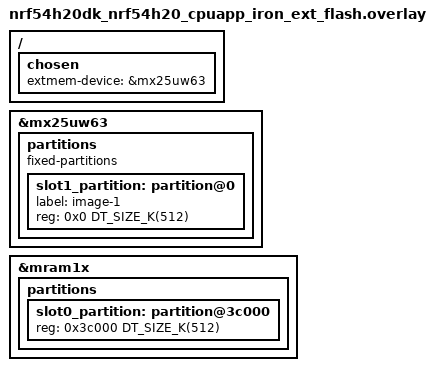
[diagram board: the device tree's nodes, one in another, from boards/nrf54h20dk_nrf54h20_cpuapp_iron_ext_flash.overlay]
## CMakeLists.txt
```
cmake_minimum_required(VERSION 3.20.0)
# Top-level CMakeLists.txt for the skeleton application.
#
# Copyright (c) 2017 Open Source Foundries Limited
#
# SPDX-License-Identifier: Apache-2.0
#
# This provides a basic application structure suitable for communication using
# mcumgr.  It can be used as a starting point for new applications.

# Standard Zephyr application boilerplate.

if (EXISTS "${CMAKE_CURRENT_SOURCE_DIR}/configuration/${BOARD}")
  message(WARNING
          "Board specific configuration will be used for ${BOARD} "
          "When providing -DOVERLAY_CONFIG= remember that all overlay "
          "configuration paths are relative to "
          "${CMAKE_CURRENT_SOURCE_DIR}/configuration/${BOARD}")
  set(APPLICATION_CONFIG_DIR "configuration/\${BOARD}")
else()
  message(NOTICE
          "Board ${BOARD} does not have board specific configuration.\n")
endif()

find_package(Zephyr REQUIRED HINTS $ENV{ZEPHYR_BASE})

project(smp_svr)

target_sources(app PRIVATE src/main.c)
target_sources_ifdef(CONFIG_MCUMGR_TRANSPORT_BT app PRIVATE src/bluetooth.c)
```

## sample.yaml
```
sample:
  description: Simple Management Protocol sample
  name: smp svr
common:
  sysbuild: true
  build_only: true
tests:
  sample.mcumgr.smp_svr.bt:
    harness: bluetooth
    tags: bluetooth
    extra_args: EXTRA_CONF_FILE="bt.conf"
    platform_allow:
      - nrf52dk/nrf52832
      - nrf52840dk/nrf52840
      - pinnacle_100_dvk
      - mg100
    integration_platforms:
      - nrf52dk/nrf52832
      - nrf52840dk/nrf52840
  sample.mcumgr.smp_svr.bt_static_svc:
    harness: bluetooth
    tags: bluetooth
    extra_args: EXTRA_CONF_FILE="bt.conf"
    extra_configs:
      - CONFIG_MCUMGR_TRANSPORT_BT_DYNAMIC_SVC_REGISTRATION=n
    platform_allow:
      - nrf52840dk/nrf52840
      - pinnacle_100_dvk
      - mg100
    integration_platforms:
      - nrf52840dk/nrf52840
  sample.mcumgr.smp_svr.udp:
    extra_args: EXTRA_CONF_FILE="udp.conf"
    platform_allow:
      - frdm_mcxn947/mcxn947/cpu0
      - mcx_n9xx_evk/mcxn947/cpu0
      - frdm_k64f
    integration_platforms:
      - frdm_k64f
  # Uses prj_no_bootloader.conf instead of prj.conf: this is the only scenario
  # built without MCUboot, so the image-management settings prj.conf carries for
  # every other scenario cannot take effect here.
  sample.mcumgr.smp_svr.udp-dtls:
    extra_args:
      - FILE_SUFFIX="no_bootloader"
      - EXTRA_CONF_FILE="udp-dtls.conf"
    platform_allow:
      - native_sim
    integration_platforms:
      - native_sim
    build_only: true
  sample.mcumgr.smp_svr.udp.802154.subg:
    extra_args: EXTRA_CONF_FILE="udp.conf;802154-subg.conf"
    platform_allow: beagleconnect_freedom
  sample.mcumgr.smp_svr.cdc:
    extra_args:
      - EXTRA_CONF_FILE="cdc.conf"
      - DTC_OVERLAY_FILE="usb.overlay"
    platform_allow:
      - frdm_mcxn947/mcxn947/cpu0
      - mcx_n9xx_evk/mcxn947/cpu0
      - nrf52833dk/nrf52820
      - nrf52833dk/nrf52833
      - nrf52840dk/nrf52840
      - nrf5340dk/nrf5340/cpuapp
      - pinnacle_100_dvk
    integration_platforms:
      - nrf52833dk/nrf52820
      - nrf52833dk/nrf52833
      - nrf52840dk/nrf52840
      - nrf5340dk/nrf5340/cpuapp
  sample.mcumgr.smp_svr.serial:
    extra_args: EXTRA_CONF_FILE="serial.conf"
    platform_allow:
      - frdm_k22f
      - frdm_k64f
      - frdm_k82f
      - frdm_ke17z
      - frdm_ke17z512
      - rddrone_fmuk66
      - twr_ke18f
      - twr_kv58f220m
      - frdm_mcxn947/mcxn947/cpu0
      - mcx_n9xx_evk/mcxn947/cpu0
      - lpcxpresso55s06
      - lpcxpresso55s16
      - lpcxpresso55s28
      - lpcxpresso55s36
      - lpcxpresso55s69/lpc55s69/cpu0
      - mimxrt1010_evk
      - mimxrt1015_evk
      - mimxrt1020_evk
      - mimxrt1024_evk
      - mimxrt1040_evk
      - mimxrt1050_evk/mimxrt1052/hyperflash
      - mimxrt1060_evk/mimxrt1062/qspi
      - mimxrt1062_fmurt6
      - mimxrt1064_evk
      - mimxrt1160_evk/mimxrt1166/cm7
      - mimxrt1170_evk/mimxrt1176/cm7
      - vmu_rt1170/mimxrt1176/cm7
      - mimxrt595_evk/mimxrt595s/cm33
      - mimxrt685_evk/mimxrt685s/cm33
      - rd_rw612_bga
      - nrf52840dk/nrf52840
      - nrf54h20dk/nrf54h20/cpuapp
      - pinnacle_100_dvk
      - mg100
    integration_platforms:
      - nrf52840dk/nrf52840
  # In mcuboot_flags test serial.conf is used for convenience as it is the simplest
  # transport. Transport does not affect flags so it does not really matter which is selected,
  # flags should affect any transport the same way.
  sample.mcumgr.smp_svr.mcuboot_flags.direct_xip_withrevert:
    extra_args:
      - EXTRA_CONF_FILE="serial.conf"
      - SB_CONFIG_MCUBOOT_MODE_DIRECT_XIP_WITH_REVERT=y
    platform_allow:
      - nrf52840dk/nrf52840
      - pinnacle_100_dvk
      - mg100
    integration_platforms:
      - nrf52840dk/nrf52840
  sample.mcumgr.smp_svr.serial-console:
    extra_args: EXTRA_CONF_FILE="serial-console.conf"
    platform_allow:
      - nrf52840dk/nrf52840
      - pinnacle_100_dvk
      - mg100
    integration_platforms:
      - nrf52840dk/nrf52840
  sample.mcumgr.smp_svr.shell:
    extra_args: EXTRA_CONF_FILE="shell.conf"
    platform_allow:
      - frdm_k22f
      - frdm_k64f
      - frdm_k82f
      - frdm_ke17z
      - frdm_ke17z512
      - rddrone_fmuk66
      - twr_ke18f
      - twr_kv58f220m
      - frdm_mcxn947/mcxn947/cpu0
      - mcx_n9xx_evk/mcxn947/cpu0
      - lpcxpresso55s06
      - lpcxpresso55s16
      - lpcxpresso55s28
      - lpcxpresso55s36
      - lpcxpresso55s69/lpc55s69/cpu0
      - mimxrt1010_evk
      - mimxrt1015_evk
      - mimxrt1020_evk
      - mimxrt1024_evk
      - mimxrt1040_evk
      - mimxrt1050_evk/mimxrt1052/hyperflash
      - mimxrt1060_evk/mimxrt1062/qspi
      - mimxrt1062_fmurt6
      - mimxrt1064_evk
      - mimxrt1160_evk/mimxrt1166/cm7
      - mimxrt1170_evk/mimxrt1176/cm7
      - vmu_rt1170/mimxrt1176/cm7
      - mimxrt595_evk/mimxrt595s/cm33
      - mimxrt685_evk/mimxrt685s/cm33
      - rd_rw612_bga
      - nrf52840dk/nrf52840
      - pinnacle_100_dvk
      - mg100
    integration_platforms:
      - nrf52840dk/nrf52840
      - mimxrt1060_evk/mimxrt1062/qspi
      - mimxrt1064_evk
  sample.mcumgr.smp_svr.shell_mgmt:
    extra_args: EXTRA_CONF_FILE="shell-mgmt.conf"
    platform_allow:
      - nrf52840dk/nrf52840
      - pinnacle_100_dvk
      - mg100
    integration_platforms:
      - nrf52840dk/nrf52840
  sample.mcumgr.smp_svr.fs:
    extra_args: EXTRA_CONF_FILE="fs.conf"
    platform_allow:
      - nrf52840dk/nrf52840
      - pinnacle_100_dvk
      - mg100
    integration_platforms:
      - nrf52840dk/nrf52840
  sample.mcumgr.smp_svr.ram_load:
    extra_args: FILE_SUFFIX="ram_load"
    platform_allow:
      - nrf52840dk/nrf52840
    integration_platforms:
      - nrf52840dk/nrf52840
  sample.mcumgr.smp_svr.ram_load.serial:
    extra_args:
      - FILE_SUFFIX="ram_load"
      - EXTRA_CONF_FILE="serial.conf"
    platform_allow:
      - nrf52840dk/nrf52840
      - mimxrt1050_evk/mimxrt1052/hyperflash
  sample.mcumgr.smp_svr.ram_load_revert.serial:
    extra_args:
      - FILE_SUFFIX="ram_load"
      - EXTRA_CONF_FILE="serial.conf"
      - SB_CONFIG_MCUBOOT_MODE_RAM_LOAD_WITH_REVERT=y
      - smp_svr_CONFIG_MCUBOOT_GENERATE_CONFIRMED_IMAGE=y
    platform_allow:
      - mimxrt1050_evk/mimxrt1052/hyperflash
    integration_platforms:
      - mimxrt1050_evk/mimxrt1052/hyperflash
  sample.mcumgr.smp_svr.raw-serial.fs:
    extra_args: EXTRA_CONF_FILE="raw-serial.conf;fs.conf"
    platform_allow:
      - nrf52840dk/nrf52840
    integration_platforms:
      - nrf52840dk/nrf52840
```

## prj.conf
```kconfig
# Enable MCUmgr and dependencies.
CONFIG_NET_BUF=y
CONFIG_ZCBOR=y
CONFIG_CRC=y
CONFIG_MCUMGR=y
CONFIG_STREAM_FLASH=y
CONFIG_FLASH_MAP=y

# Some command handlers require a large stack.
CONFIG_SYSTEM_WORKQUEUE_STACK_SIZE=2304
CONFIG_MAIN_STACK_SIZE=2176

# Ensure an MCUboot-compatible binary is generated.
CONFIG_BOOTLOADER_MCUBOOT=y

# Enable flash operations.
CONFIG_FLASH=y

# Required by the `taskstat` command.
CONFIG_THREAD_MONITOR=y

# Support for taskstat command
CONFIG_MCUMGR_GRP_OS_TASKSTAT=y

# Enable statistics and statistic names.
CONFIG_STATS=y
CONFIG_STATS_NAMES=y

# Enable most core commands.
CONFIG_FLASH=y
CONFIG_IMG_MANAGER=y
CONFIG_MCUMGR_GRP_IMG=n
CONFIG_MCUMGR_GRP_OS=y
CONFIG_MCUMGR_GRP_STAT=y

# Enable logging
CONFIG_LOG=y
CONFIG_MCUBOOT_UTIL_LOG_LEVEL_WRN=n

# Disable debug logging
CONFIG_LOG_MAX_LEVEL=3
```

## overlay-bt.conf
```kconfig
CONFIG_BT=y
CONFIG_BT_PERIPHERAL=y

# Allow for large Bluetooth data packets.
CONFIG_BT_L2CAP_TX_MTU=498
CONFIG_BT_BUF_ACL_RX_SIZE=502
CONFIG_BT_BUF_ACL_TX_SIZE=502
CONFIG_BT_CTLR_DATA_LENGTH_MAX=251

# Enable the Bluetooth mcumgr transport (unauthenticated).
CONFIG_MCUMGR_TRANSPORT_BT=y
CONFIG_MCUMGR_TRANSPORT_BT_AUTHEN=n
CONFIG_MCUMGR_TRANSPORT_BT_CONN_PARAM_CONTROL=y

# Enable the Shell mcumgr transport.
CONFIG_BASE64=y
CONFIG_CRC=y
CONFIG_SHELL=y
CONFIG_SHELL_BACKEND_SERIAL=y
CONFIG_MCUMGR_TRANSPORT_SHELL=y

# Enable the mcumgr Packet Reassembly feature over Bluetooth and its configuration dependencies.
# MCUmgr buffer size is optimized to fit one SMP packet divided into five Bluetooth Write Commands,
# transmitted with the maximum possible MTU value: 498 bytes.
CONFIG_MCUMGR_TRANSPORT_BT_REASSEMBLY=y
CONFIG_MCUMGR_TRANSPORT_NETBUF_SIZE=2475
CONFIG_MCUMGR_GRP_OS_MCUMGR_PARAMS=y
CONFIG_MCUMGR_TRANSPORT_WORKQUEUE_STACK_SIZE=4608

CONFIG_MCUMGR_TRANSPORT_BT_CONN_PARAM_CONTROL_MIN_INT=30
CONFIG_MCUMGR_TRANSPORT_BT_CONN_PARAM_CONTROL_MAX_INT=50
CONFIG_MCUMGR_TRANSPORT_BT_CONN_PARAM_CONTROL_TIMEOUT=400
CONFIG_BT_PERIPHERAL_PREF_MIN_INT=30
CONFIG_BT_PERIPHERAL_PREF_MAX_INT=50
CONFIG_BT_PERIPHERAL_PREF_TIMEOUT=400

# Enable the LittleFS file system.
CONFIG_FILE_SYSTEM=y
CONFIG_FILE_SYSTEM_LITTLEFS=y

# Enable file system commands
CONFIG_MCUMGR_GRP_FS=y

# Enable the storage erase command.
CONFIG_MCUMGR_GRP_ZBASIC=y
CONFIG_MCUMGR_GRP_ZBASIC_STORAGE_ERASE=y

# Disable Bluetooth ping support
CONFIG_BT_CTLR_LE_PING=n

# Disable shell commands that are not needed
CONFIG_CLOCK_CONTROL_NRF_SHELL=n
CONFIG_DEVICE_SHELL=n
CONFIG_DEVMEM_SHELL=n
CONFIG_FLASH_SHELL=n
```

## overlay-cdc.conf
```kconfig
# Enable USB subsystem
CONFIG_USB_DEVICE_STACK=y
CONFIG_SERIAL=y
CONFIG_UART_LINE_CTRL=y
CONFIG_USB_DEVICE_INITIALIZE_AT_BOOT=n
CONFIG_CONSOLE=y
# USB backend is serial device
CONFIG_MCUMGR_SMP_UART=y
```

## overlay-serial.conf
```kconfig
# Enable the serial mcumgr transport.
CONFIG_MCUMGR_SMP_UART=y
CONFIG_CONSOLE=y
```

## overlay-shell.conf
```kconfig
# Enable the shell mcumgr transport.
CONFIG_SHELL=y
CONFIG_SHELL_BACKEND_SERIAL=y
CONFIG_MCUMGR_SMP_SHELL=y

# mcumgr-cli application doesn't accepts log in the channel it uses
CONFIG_SHELL_LOG_BACKEND=n
```

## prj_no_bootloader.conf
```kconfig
# Variant of prj.conf for the scenarios that build without a bootloader.
#
# prj.conf turns on image management, which only makes sense when MCUboot owns a
# second slot. Without a bootloader IMG_MANAGER stays off, and with it both
# MCUMGR_GRP_IMG and the whole MCUBOOT_UTIL log level choice become unreachable,
# so those assignments could never take effect here. The rest is identical to
# prj.conf.

# Enable MCUmgr and dependencies.
CONFIG_NET_BUF=y
CONFIG_ZCBOR=y
CONFIG_CRC=y
CONFIG_MCUMGR=y
CONFIG_STREAM_FLASH=y
CONFIG_FLASH_MAP=y

# Some command handlers require a large stack.
CONFIG_SYSTEM_WORKQUEUE_STACK_SIZE=2304
CONFIG_MAIN_STACK_SIZE=2176

# Enable flash operations.
CONFIG_FLASH=y

# Required by the `taskstat` command.
CONFIG_THREAD_MONITOR=y

# Support for taskstat command
CONFIG_MCUMGR_GRP_OS_TASKSTAT=y

# Enable statistics and statistic names.
CONFIG_STATS=y
CONFIG_STATS_NAMES=y

# Enable most core commands.
CONFIG_FLASH=y
# Ineffective without a bootloader: MCUMGR_GRP_IMG depends on IMG_MANAGER.
# CONFIG_IMG_MANAGER=y
# CONFIG_MCUMGR_GRP_IMG=y
CONFIG_MCUMGR_GRP_OS=y
CONFIG_MCUMGR_GRP_STAT=y

# Enable logging
CONFIG_LOG=y
# Ineffective without a bootloader: the MCUBOOT_UTIL log level choice only
# exists once IMG_MANAGER pulls in MCUBOOT_BOOTUTIL_LIB.
# CONFIG_MCUBOOT_UTIL_LOG_LEVEL_WRN=y

# Disable debug logging
CONFIG_LOG_MAX_LEVEL=3
```

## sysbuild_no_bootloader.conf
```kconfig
# Companion of prj_no_bootloader.conf: build the application on its own.
SB_CONFIG_BOOTLOADER_NONE=y
```

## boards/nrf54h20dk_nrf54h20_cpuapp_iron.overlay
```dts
/ {
	sram@22007FC0 {
		compatible = "zephyr,memory-region", "mmio-sram";
		reg = <0x22007FC0 0x40>;
		zephyr,memory-region = "RetainedMem";
		status = "okay";

		retainedmem {
			compatible = "zephyr,retained-ram";
			status = "okay";
			#address-cells = <1>;
			#size-cells = <1>;

			boot_info0: boot_info@0 {
				compatible = "zephyr,retention";
				status = "okay";
				reg = <0x0 0x40>;
			};
		};
	};

	chosen {
		zephyr,bootloader-info = &boot_info0;
	};
};

&cpuapp_ram0 {
	reg = <0x22000000 0x7FC0>;
};
```

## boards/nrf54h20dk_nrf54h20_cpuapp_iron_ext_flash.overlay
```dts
/*
 * Copyright (c) 2025 Nordic Semiconductor ASA
 *
 * SPDX-License-Identifier: LicenseRef-Nordic-5-Clause
 */

/delete-node/ &slot1_partition;

/ {
	chosen {
		extmem-device = &mx25uw63;
	};
};

&mx25uw63 {
	status = "okay";
	partitions {
		compatible = "fixed-partitions";
		#address-cells = <1>;
		#size-cells = <1>;

		slot1_partition: partition@0 {
			label = "image-1";
			reg = <0x0 DT_SIZE_K(512)>;
		};
	};
};

&mram1x {
	partitions {
		slot0_partition: partition@3c000 {
			reg = <0x3c000 DT_SIZE_K(512)>;
		};
	};
};
```

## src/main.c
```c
/*
 * Copyright (c) 2012-2014 Wind River Systems, Inc.
 * Copyright (c) 2020 Prevas A/S
 *
 * SPDX-License-Identifier: Apache-2.0
 */

#include <zephyr/kernel.h>
#include <zephyr/stats/stats.h>
#include <zephyr/usb/usb_device.h>

#ifdef CONFIG_MCUMGR_GRP_FS
#include <zephyr/device.h>
#include <zephyr/fs/fs.h>
#include <zephyr/fs/littlefs.h>
#endif
#ifdef CONFIG_MCUMGR_GRP_STAT
#include <zephyr/mgmt/mcumgr/grp/stat_mgmt/stat_mgmt.h>
#endif

#define LOG_LEVEL LOG_LEVEL_DBG
#include <zephyr/logging/log.h>
LOG_MODULE_REGISTER(smp_sample);

#include "common.h"

#include <zephyr/retention/blinfo.h>
#include <bootutil/image.h>

#define STORAGE_PARTITION_LABEL	storage_partition
#define STORAGE_PARTITION_ID	FIXED_PARTITION_ID(STORAGE_PARTITION_LABEL)

/* Define an example stats group; approximates seconds since boot. */
STATS_SECT_START(smp_svr_stats)
STATS_SECT_ENTRY(ticks)
STATS_SECT_END;

/* Assign a name to the `ticks` stat. */
STATS_NAME_START(smp_svr_stats)
STATS_NAME(smp_svr_stats, ticks)
STATS_NAME_END(smp_svr_stats);

/* Define an instance of the stats group. */
STATS_SECT_DECL(smp_svr_stats) smp_svr_stats;

#ifdef CONFIG_MCUMGR_GRP_FS
FS_LITTLEFS_DECLARE_DEFAULT_CONFIG(cstorage);
static struct fs_mount_t littlefs_mnt = {
	.type = FS_LITTLEFS,
	.fs_data = &cstorage,
	.storage_dev = (void *)STORAGE_PARTITION_ID,
	.mnt_point = "/lfs1"
};
#endif

static void blinfo_bootloader_version(void)
{
	struct image_version version = {0x00};

	int ret = blinfo_lookup(BLINFO_BOOTLOADER_VERSION,
				(char *)&version,
				sizeof(struct image_version));

	if (ret < 0) {
		printf("blinfo_lookup error: %d\n", ret);
	} else {
		printf("bl iv_major: %d\n", version.iv_major);
		printf("bl iv_minor: %d\n", version.iv_minor);
		printf("bl iv_revision: %d\n", version.iv_revision);
		printf("bl iv_build_num: %d\n", version.iv_build_num);
	}
}

int main(void)
{
	int rc = STATS_INIT_AND_REG(smp_svr_stats, STATS_SIZE_32,
				    "smp_svr_stats");

	if (rc < 0) {
		LOG_ERR("Error initializing stats system [%d]", rc);
	}

	/* Register the built-in mcumgr command handlers. */
#ifdef CONFIG_MCUMGR_GRP_FS
	rc = fs_mount(&littlefs_mnt);
	if (rc < 0) {
		LOG_ERR("Error mounting littlefs [%d]", rc);
	}
#endif

#ifdef CONFIG_MCUMGR_TRANSPORT_BT
	start_smp_bluetooth_adverts();
#endif

	if (IS_ENABLED(CONFIG_USB_DEVICE_STACK)) {
		rc = usb_enable(NULL);

		/* Ignore EALREADY error as USB CDC is likely already initialised */
		if (rc != 0 && rc != -EALREADY) {
			LOG_ERR("Failed to enable USB");
			return 0;
		}
	}
	/* using __TIME__ ensure that a new binary will be built on every
	 * compile which is convenient when testing firmware upgrade.
	 */
	LOG_INF("build time: " __DATE__ " " __TIME__);

	blinfo_bootloader_version();

	/* The system work queue handles all incoming mcumgr requests.  Let the
	 * main thread idle while the mcumgr server runs.
	 */
	while (1) {
		k_sleep(K_MSEC(1000));
		STATS_INC(smp_svr_stats, ticks);
	}
	return 0;
}
```

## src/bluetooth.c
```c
/*
 * Copyright (c) 2012-2014 Wind River Systems, Inc.
 * Copyright (c) 2020 Prevas A/S
 *
 * SPDX-License-Identifier: Apache-2.0
 */

#include <zephyr/bluetooth/bluetooth.h>
#include <zephyr/bluetooth/conn.h>
#include <zephyr/bluetooth/gatt.h>
#include <zephyr/bluetooth/hci.h>
#include <zephyr/mgmt/mcumgr/transport/smp_bt.h>

#define LOG_LEVEL LOG_LEVEL_DBG
#include <zephyr/logging/log.h>
LOG_MODULE_REGISTER(smp_bt_sample);

static struct k_work advertise_work;

static const struct bt_data ad[] = {
	BT_DATA_BYTES(BT_DATA_FLAGS, (BT_LE_AD_GENERAL | BT_LE_AD_NO_BREDR)),
	BT_DATA_BYTES(BT_DATA_UUID128_ALL, SMP_BT_SVC_UUID_VAL),
};

static const struct bt_data sd[] = {
	BT_DATA(BT_DATA_NAME_COMPLETE, CONFIG_BT_DEVICE_NAME, sizeof(CONFIG_BT_DEVICE_NAME) - 1),
};

static void advertise(struct k_work *work)
{
	int rc;

	rc = bt_le_adv_start(BT_LE_ADV_CONN_FAST_1, ad, ARRAY_SIZE(ad), sd, ARRAY_SIZE(sd));
	if (rc) {
		LOG_ERR("Advertising failed to start (rc %d)", rc);
		return;
	}

	LOG_INF("Advertising successfully started");
}

static void connected(struct bt_conn *conn, uint8_t err)
{
	if (err) {
		LOG_ERR("Connection failed, err 0x%02x %s", err, bt_hci_err_to_str(err));
		k_work_submit(&advertise_work);
	} else {
		struct bt_conn_info info;
		char peer[BT_ADDR_LE_STR_LEN] = "unknown";
		char local[BT_ADDR_LE_STR_LEN] = "unknown";
		int rc;

		rc = bt_conn_get_info(conn, &info);
		if (rc) {
			LOG_WRN("Failed to get connection info (rc %d)", rc);
		} else {
			bt_addr_le_to_str(info.le.remote, peer, sizeof(peer));
			bt_addr_le_to_str(info.le.local, local, sizeof(local));
		}

		LOG_INF("Connected, peer %s, local %s", peer, local);
	}
}

static void disconnected(struct bt_conn *conn, uint8_t reason)
{
	struct bt_conn_info info;
	char peer[BT_ADDR_LE_STR_LEN] = "unknown";
	int rc;

	rc = bt_conn_get_info(conn, &info);
	if (rc) {
		LOG_WRN("Failed to get connection info (rc %d)", rc);
	} else {
		bt_addr_le_to_str(info.le.remote, peer, sizeof(peer));
	}

	LOG_INF("Disconnected, reason 0x%02x %s, peer %s", reason,
		bt_hci_err_to_str(reason), peer);
}

static void on_conn_recycled(void)
{
	k_work_submit(&advertise_work);
}

BT_CONN_CB_DEFINE(conn_callbacks) = {
	.connected = connected,
	.disconnected = disconnected,
	.recycled = on_conn_recycled,
};

static void bt_ready(int err)
{
	if (err != 0) {
		LOG_ERR("Bluetooth failed to initialise: %d", err);
	} else {
		k_work_submit(&advertise_work);
	}
}

void start_smp_bluetooth_adverts(void)
{
	int rc;

	k_work_init(&advertise_work, advertise);
	rc = bt_enable(bt_ready);

	if (rc != 0) {
		LOG_ERR("Bluetooth enable failed: %d", rc);
	}
}
```
